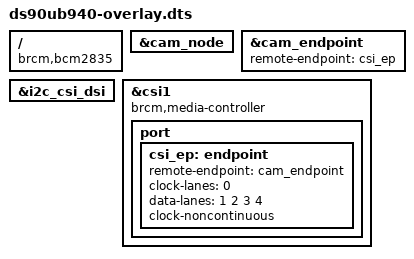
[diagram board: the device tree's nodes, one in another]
// SPDX-License-Identifier: GPL-2.0-only
// Definitions for DS90UB940 deserializer on VC I2C bus
/dts-v1/;
/plugin/;

#include <dt-bindings/gpio/gpio.h>

/{
	compatible = "brcm,bcm2835";

	i2c_frag: fragment@100 {
		target = <&i2c_csi_dsi>;
		__overlay__ {
			#address-cells = <1>;
			#size-cells = <0>;
			status = "okay";

			#include "ds90ub940.dtsi"
		};
	};

	csi_frag: fragment@101 {
		target = <&csi1>;
		csi: __overlay__ {
			status = "okay";
			brcm,media-controller;

			port {
				csi_ep: endpoint {
					remote-endpoint = <&cam_endpoint>;
					clock-lanes = <0>;
					data-lanes = <1 2 3 4>;
					clock-noncontinuous;
				};
			};
		};
	};

	__overrides__ {
		media-controller = <&csi>,"brcm,media-controller?";
		cam0 = <&i2c_frag>, "target:0=",<&i2c_csi_dsi0>,
		       <&csi_frag>, "target:0=",<&csi0>;
		link-frequency = <&cam_endpoint>,"link-frequencies#0";
	};
};

&cam_node {
	status = "okay";
};

&cam_endpoint {
	remote-endpoint = <&csi_ep>;
};
